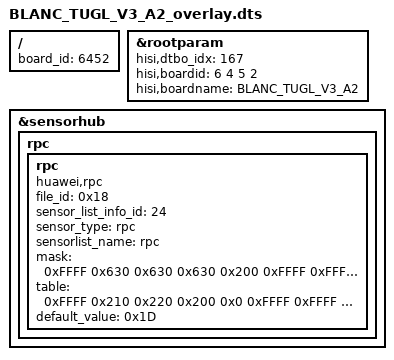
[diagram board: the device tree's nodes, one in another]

/**
 * Copyright (C) 2014 Hisilicon Ltd.
 *
 *  This program is free software; you can redistribute it and/or modify
 *  it under the terms of the GNU General Public License version 2 as
 *  publishhed by the Free Software Foundation.
 */

/dts-v1/;
/plugin/;
/include/ "BLANC_TUGL_V1_overlay.dtsi"

/ {
	board_id = <6452>;
};

&rootparam {
        hisi,dtbo_idx = <167>;
    hisi,boardid = <6 4 5 2>;
    hisi,boardname = "BLANC_TUGL_V3_A2";
};

	&sensorhub{
		rpc{
           		 rpc{
				compatible = "huawei,rpc";
				file_id = <0x18>;
				sensor_list_info_id = <24>;
				sensor_type = "rpc";
				sensorlist_name = "rpc";
				mask = <0xFFFF 0x630 0x630 0x630 0x200 0xFFFF 0xFFFF 0xFFFF
						0xFFFF 0xFFFF 0xFFFF 0xFFFF 0xFFFF 0xFFFF 0xFFFF 0xFFFF
						0xFFFF 0xFFFF 0xFFFF 0xFFFF 0xFFFF 0xFFFF 0xFFFF 0xFFFF
						0xFFFF 0xFFFF 0xFFFF 0xFFFF 0xFFFF 0xFFFF 0xFFFF 0xFFFF>;
				table = <0xFFFF 0x210 0x220 0x200 0x0 0xFFFF 0xFFFF 0xFFFF
						 0xFFFF 0xFFFF 0xFFFF 0xFFFF 0xFFFF 0xFFFF 0xFFFF 0xFFFF
						 0xFFFF 0xFFFF 0xFFFF 0xFFFF 0xFFFF 0xFFFF 0xFFFF 0xFFFF
						 0xFFFF 0xFFFF 0xFFFF 0xFFFF 0xFFFF 0xFFFF 0xFFFF 0xFFFF>;
				default_value = <0x1D>;
				status = "ok";
			};
        	};
	};

